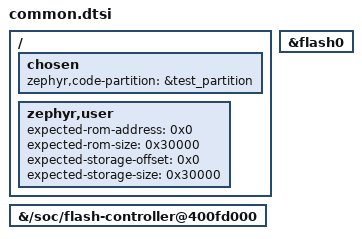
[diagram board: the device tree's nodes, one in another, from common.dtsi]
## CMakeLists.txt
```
# SPDX-FileCopyrightText: Copyright The Zephyr Project Contributors
# SPDX-License-Identifier: Apache-2.0

cmake_minimum_required(VERSION 3.28.0)

find_package(Zephyr REQUIRED HINTS $ENV{ZEPHYR_BASE})
project(mapped_partition)

target_sources(app PRIVATE
  src/main.c
)

if(TEST_OVERFLOW_IMAGE)
  target_sources(app PRIVATE
    src/overflow.c
  )
endif()

if(CONFIG_CMAKE_LINKER_GENERATOR)
  dt_prop(expected_rom_address PATH "/zephyr,user" PROPERTY "expected-rom-address")

  zephyr_linker_symbol(SYMBOL test_rom_address
    EXPR "ASSERT(ORIGIN(FLASH) == ${expected_rom_address}, \\\"Unexpected ROM address\\\")"
  )
  if(NOT TEST_OVERFLOW_IMAGE)
    dt_prop(expected_rom_size PATH "/zephyr,user" PROPERTY "expected-rom-size")
    math(EXPR expected_rom_size "${expected_rom_size} - ${CONFIG_ROM_END_OFFSET}")

    zephyr_linker_symbol(SYMBOL test_rom_size
      EXPR "ASSERT(LENGTH(FLASH) == ${expected_rom_size}, \\\"Unexpected ROM size\\\")"
    )
  endif()
else()
  zephyr_linker_sources(SECTIONS
    rom_assert.ld
  )
  if(NOT TEST_OVERFLOW_IMAGE)
    zephyr_linker_sources(SECTIONS
      rom_size_assert.ld
    )
  endif()
endif()

if(TEST_OVERFLOW_CHECK)
  enable_testing()
  include(CTest)
  configure_file(check_overflow.cmake.in check_overflow.cmake @ONLY)
  add_test(NAME mapped_partition_storage_overflow
    COMMAND "${CMAKE_COMMAND}" -P "${CMAKE_CURRENT_BINARY_DIR}/check_overflow.cmake"
  )
endif()
```

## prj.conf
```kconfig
# SPDX-FileCopyrightText: Copyright The Zephyr Project Contributors
# SPDX-License-Identifier: Apache-2.0

CONFIG_ZTEST=y
CONFIG_USE_DT_CODE_PARTITION=y
CONFIG_ROM_END_OFFSET=0x1000
```

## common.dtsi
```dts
/*
 * SPDX-FileCopyrightText: Copyright The Zephyr Project Contributors
 * SPDX-License-Identifier: Apache-2.0
 */

/ {
	chosen {
		zephyr,code-partition = &test_partition;
	};

	zephyr,user {
		expected-rom-address = <0x0>;
		expected-rom-size = <0x30000>;
		expected-storage-offset = <0x0>;
		expected-storage-size = <0x30000>;
	};
};

&{/soc/flash-controller@400fd000} {
	ranges;
};

&flash0 {
	ranges = <0x0 0x0 0x40000>;
	#address-cells = <1>;
	#size-cells = <1>;
};
```

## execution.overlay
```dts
/*
 * SPDX-FileCopyrightText: Copyright The Zephyr Project Contributors
 * SPDX-License-Identifier: Apache-2.0
 */

#include "common.dtsi"

&flash0 {
	test_partition: partition@10000 {
		compatible = "zephyr,mapped-partition";
		reg = <0x10000 0x30000>, <0x0 0x20000>;
		reg-names = "cpu-mapped", "execution";
	};
};

&{/zephyr,user} {
	expected-rom-size = <0x20000>;
	expected-storage-offset = <0x10000>;
};
```

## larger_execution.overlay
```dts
/*
 * SPDX-FileCopyrightText: Copyright The Zephyr Project Contributors
 * SPDX-License-Identifier: Apache-2.0
 */

#include "common.dtsi"

&flash0 {
	test_partition: partition@10000 {
		compatible = "zephyr,mapped-partition";
		reg = <0x10000 0x20000>, <0x0 0x30000>;
		reg-names = "cpu-mapped", "execution";
	};
};

&{/zephyr,user} {
	expected-rom-size = <0x20000>;
	expected-storage-offset = <0x10000>;
	expected-storage-size = <0x20000>;
};
```

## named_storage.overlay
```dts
/*
 * SPDX-FileCopyrightText: Copyright The Zephyr Project Contributors
 * SPDX-License-Identifier: Apache-2.0
 */

#include "unnamed.overlay"

&test_partition {
	reg-names = "cpu-mapped";
};
```

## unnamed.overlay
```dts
/*
 * SPDX-FileCopyrightText: Copyright The Zephyr Project Contributors
 * SPDX-License-Identifier: Apache-2.0
 */

#include "common.dtsi"

&flash0 {
	test_partition: partition@0 {
		compatible = "zephyr,mapped-partition";
		reg = <0x0 0x30000>;
	};
};
```

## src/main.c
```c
/*
 * SPDX-FileCopyrightText: Copyright The Zephyr Project Contributors
 * SPDX-License-Identifier: Apache-2.0
 */

#include <zephyr/devicetree.h>
#include <zephyr/ztest.h>

#define TEST_PARTITION DT_CHOSEN(zephyr_code_partition)
#define TEST_EXPECTED  DT_PATH(zephyr_user)

ZTEST(mapped_partition, test_storage_region)
{
	zassert_equal(DT_MAPPED_PARTITION_OFFSET(TEST_PARTITION),
		      DT_PROP(TEST_EXPECTED, expected_storage_offset));
	zassert_equal(DT_REG_SIZE(TEST_PARTITION), DT_PROP(TEST_EXPECTED, expected_storage_size));
}

ZTEST_SUITE(mapped_partition, NULL, NULL, NULL, NULL, NULL);
```

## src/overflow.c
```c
/*
 * SPDX-FileCopyrightText: Copyright The Zephyr Project Contributors
 * SPDX-License-Identifier: Apache-2.0
 */

#include <stdint.h>

#include <zephyr/toolchain.h>

/* Fits the execution region, but exceeds storage after reserving ROM_END_OFFSET. */
static const uint8_t overflow_payload[0x20000] = {1};

LINKER_KEEP(overflow_payload);
```
